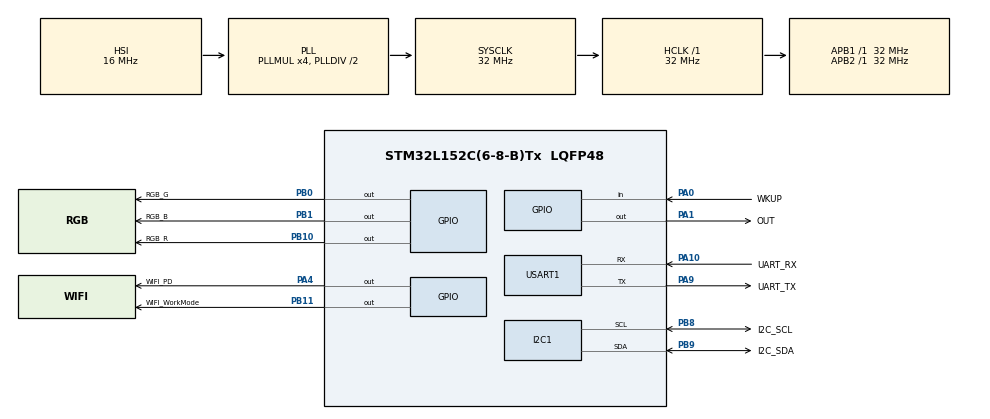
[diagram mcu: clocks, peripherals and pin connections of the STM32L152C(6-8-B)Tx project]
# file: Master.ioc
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Dma.I2C1_RX.2.Direction=DMA_PERIPH_TO_MEMORY
Dma.I2C1_RX.2.Instance=DMA1_Channel7
Dma.I2C1_RX.2.MemDataAlignment=DMA_MDATAALIGN_BYTE
Dma.I2C1_RX.2.MemInc=DMA_MINC_ENABLE
Dma.I2C1_RX.2.Mode=DMA_NORMAL
Dma.I2C1_RX.2.PeriphDataAlignment=DMA_PDATAALIGN_BYTE
Dma.I2C1_RX.2.PeriphInc=DMA_PINC_DISABLE
Dma.I2C1_RX.2.Priority=DMA_PRIORITY_MEDIUM
Dma.I2C1_TX.3.Direction=DMA_MEMORY_TO_PERIPH
Dma.I2C1_TX.3.Instance=DMA1_Channel6
Dma.I2C1_TX.3.MemDataAlignment=DMA_MDATAALIGN_BYTE
Dma.I2C1_TX.3.MemInc=DMA_MINC_ENABLE
Dma.I2C1_TX.3.Mode=DMA_NORMAL
Dma.I2C1_TX.3.PeriphDataAlignment=DMA_PDATAALIGN_BYTE
Dma.I2C1_TX.3.PeriphInc=DMA_PINC_DISABLE
Dma.I2C1_TX.3.Priority=DMA_PRIORITY_MEDIUM
Dma.Request0=USART1_RX
Dma.Request1=USART1_TX
Dma.Request2=I2C1_RX
Dma.Request3=I2C1_TX
Dma.USART1_RX.0.Direction=DMA_PERIPH_TO_MEMORY
Dma.USART1_RX.0.Instance=DMA1_Channel5
Dma.USART1_RX.0.MemDataAlignment=DMA_MDATAALIGN_BYTE
Dma.USART1_RX.0.MemInc=DMA_MINC_ENABLE
Dma.USART1_RX.0.Mode=DMA_NORMAL
Dma.USART1_RX.0.PeriphDataAlignment=DMA_PDATAALIGN_BYTE
Dma.USART1_RX.0.PeriphInc=DMA_PINC_DISABLE
Dma.USART1_RX.0.Priority=DMA_PRIORITY_HIGH
Dma.USART1_TX.1.Direction=DMA_MEMORY_TO_PERIPH
Dma.USART1_TX.1.Instance=DMA1_Channel4
Dma.USART1_TX.1.MemDataAlignment=DMA_MDATAALIGN_BYTE
Dma.USART1_TX.1.MemInc=DMA_MINC_ENABLE
Dma.USART1_TX.1.Mode=DMA_NORMAL
Dma.USART1_TX.1.PeriphDataAlignment=DMA_PDATAALIGN_BYTE
Dma.USART1_TX.1.PeriphInc=DMA_PINC_DISABLE
Dma.USART1_TX.1.Priority=DMA_PRIORITY_MEDIUM
FREERTOS.Tasks01=defaultTask,0,128,StartDefaultTask,Default
I2C1.DualAddressMode=I2C_DUALADDRESS_ENABLE
I2C1.GeneralCallMode=I2C_GENERALCALL_ENABLE
I2C1.I2C_Mode=I2C_Fast
I2C1.OwnAddress=4
Mcu.Family=STM32L1
Mcu.Name=STM32L152C(6-8-B)Tx
Mcu.Package=LQFP48
NVIC.DMA1_Channel4_IRQn=true\:5\:0\:false\:false\:true\:true
NVIC.DMA1_Channel5_IRQn=true\:5\:0\:false\:false\:true\:true
NVIC.DMA1_Channel6_IRQn=true\:5\:0\:false\:false\:true\:true
NVIC.DMA1_Channel7_IRQn=true\:5\:0\:false\:false\:true\:true
NVIC.FLASH_IRQn=true\:5\:0\:false\:false\:true\:true
NVIC.I2C1_ER_IRQn=true\:5\:0\:false\:false\:true\:true
NVIC.I2C1_EV_IRQn=true\:5\:0\:false\:false\:true\:true
NVIC.PriorityGroup=NVIC_PRIORITYGROUP_4
NVIC.TIM2_IRQn=true\:0\:0\:false\:false\:true\:false
NVIC.TimeBase=TIM2_IRQn
NVIC.TimeBaseIP=TIM2
NVIC.USART1_IRQn=true\:5\:0\:false\:false\:true\:true
PA0-WKUP1.GPIO_Label=WKUP
PA0-WKUP1.Signal=GPIO_Input
PA1.GPIO_Label=OUT
PA1.Signal=GPIO_Output
PA10.GPIO_Label=UART_RX
PA10.Mode=Asynchronous
PA10.Signal=USART1_RX
PA13.Mode=Serial_Wire
PA13.Signal=SYS_JTMS-SWDIO
PA14.Mode=Serial_Wire
PA14.Signal=SYS_JTCK-SWCLK
PA4.GPIO_Label=WIFI_PD
PA4.Signal=GPIO_Output
PA9.GPIO_Label=UART_TX
PA9.Mode=Asynchronous
PA9.Signal=USART1_TX
PB0.GPIO_Label=RGB_G
PB0.Signal=GPIO_Output
PB1.GPIO_Label=RGB_B
PB1.Signal=GPIO_Output
PB10.GPIO_Label=RGB_R
PB10.Signal=GPIO_Output
PB11.GPIO_Label=WIFI_WorkMode
PB11.GPIO_PuPd=GPIO_PULLDOWN
PB11.Signal=GPIO_Output
PB8.GPIO_Label=I2C_SCL
PB8.Mode=I2C
PB8.Signal=I2C1_SCL
PB9.GPIO_Label=I2C_SDA
PB9.Mode=I2C
PB9.Signal=I2C1_SDA
ProjectManager.HeapSize=0x200
ProjectManager.StackSize=0x400
ProjectManager.TargetToolchain=MDK-ARM V5
RCC.AHBFreq_Value=32000000
RCC.APB1Freq_Value=32000000
RCC.APB1TimFreq_Value=32000000
RCC.APB2Freq_Value=32000000
RCC.APB2TimFreq_Value=32000000
RCC.HCLKFreq_Value=32000000
RCC.HSE_VALUE=24000000
RCC.HSI_VALUE=16000000
RCC.LSE_VALUE=32768
RCC.MSIClockRange=RCC_MSIRANGE_6
RCC.MSI_VALUE=4194000
RCC.PLLMUL=RCC_PLL_MUL4
RCC.SYSCLKFreq_VALUE=32000000
RCC.SYSCLKSource=RCC_SYSCLKSOURCE_PLLCLK
RCC.USBOutput=32000000
RCC.VCOOutputFreq_Value=64000000
VP_FREERTOS_VS_ENABLE.Mode=Enabled
VP_SYS_VS_tim2.Mode=TIM2
board=Master

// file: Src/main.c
/**
  ******************************************************************************
  * File Name          : main.c
  * Description        : Main program body
  ******************************************************************************
  *
  * COPYRIGHT(c) 2016 STMicroelectronics
  *
  * Redistribution and use in source and binary forms, with or without modification,
  * are permitted provided that the following conditions are met:
  *   1. Redistributions of source code must retain the above copyright notice,
  *      this list of conditions and the following disclaimer.
  *   2. Redistributions in binary form must reproduce the above copyright notice,
  *      this list of conditions and the following disclaimer in the documentation
  *      and/or other materials provided with the distribution.
  *   3. Neither the name of STMicroelectronics nor the names of its contributors
  *      may be used to endorse or promote products derived from this software
  *      without specific prior written permission.
  *
  * THIS SOFTWARE IS PROVIDED BY THE COPYRIGHT HOLDERS AND CONTRIBUTORS "AS IS"
  * AND ANY EXPRESS OR IMPLIED WARRANTIES, INCLUDING, BUT NOT LIMITED TO, THE
  * IMPLIED WARRANTIES OF MERCHANTABILITY AND FITNESS FOR A PARTICULAR PURPOSE ARE
  * DISCLAIMED. IN NO EVENT SHALL THE COPYRIGHT HOLDER OR CONTRIBUTORS BE LIABLE
  * FOR ANY DIRECT, INDIRECT, INCIDENTAL, SPECIAL, EXEMPLARY, OR CONSEQUENTIAL
  * DAMAGES (INCLUDING, BUT NOT LIMITED TO, PROCUREMENT OF SUBSTITUTE GOODS OR
  * SERVICES; LOSS OF USE, DATA, OR PROFITS; OR BUSINESS INTERRUPTION) HOWEVER
  * CAUSED AND ON ANY THEORY OF LIABILITY, WHETHER IN CONTRACT, STRICT LIABILITY,
  * OR TORT (INCLUDING NEGLIGENCE OR OTHERWISE) ARISING IN ANY WAY OUT OF THE USE
  * OF THIS SOFTWARE, EVEN IF ADVISED OF THE POSSIBILITY OF SUCH DAMAGE.
  *
  ******************************************************************************
  */
#include "stm32l1xx_hal.h"
#include "cmsis_os.h"
#include "dma.h"
#include "i2c.h"
#include "usart.h"
#include "gpio.h"

/* USER CODE BEGIN Includes */
#include <string.h>
#include "main.h"
/* USER CODE END Includes */

/* USER CODE BEGIN PV */
/* Private variables ---------------------------------------------------------*/

/* USER CODE END PV */

void SystemClock_Config(void);
void Error_Handler(void);
void MX_FREERTOS_Init(void);

/* USER CODE BEGIN PFP */
/* Private function prototypes -----------------------------------------------*/

/* USER CODE END PFP */

int main(void)
{

  /* MCU Configuration----------------------------------------------------------*/

  /* Reset of all peripherals, Initializes the Flash interface and the Systick. */
  HAL_Init();

  /* Configure the system clock */
  SystemClock_Config();

  /* Initialize all configured peripherals */
  MX_GPIO_Init();
  MX_DMA_Init();
  MX_I2C1_Init();
  MX_USART1_UART_Init();

  /* Call init function for freertos objects (in freertos.c) */
  MX_FREERTOS_Init();

  /* Start scheduler */
  osKernelStart();

  /* We should never get here as control is now taken by the scheduler */

  /* Infinite loop */
  while (1)
  {

  }

}

/** System Clock Configuration
*/
void SystemClock_Config(void)
{

  RCC_OscInitTypeDef RCC_OscInitStruct;
  RCC_ClkInitTypeDef RCC_ClkInitStruct;

  __HAL_RCC_PWR_CLK_ENABLE();

  __HAL_PWR_VOLTAGESCALING_CONFIG(PWR_REGULATOR_VOLTAGE_SCALE1);

  RCC_OscInitStruct.OscillatorType = RCC_OSCILLATORTYPE_HSI;
  RCC_OscInitStruct.HSIState = RCC_HSI_ON;
  RCC_OscInitStruct.HSICalibrationValue = 16;
  RCC_OscInitStruct.PLL.PLLState = RCC_PLL_ON;
  RCC_OscInitStruct.PLL.PLLSource = RCC_PLLSOURCE_HSI;
  RCC_OscInitStruct.PLL.PLLMUL = RCC_PLL_MUL4;
  RCC_OscInitStruct.PLL.PLLDIV = RCC_PLL_DIV2;
  if (HAL_RCC_OscConfig(&RCC_OscInitStruct) != HAL_OK)
  {
    Error_Handler();
  }

  RCC_ClkInitStruct.ClockType = RCC_CLOCKTYPE_HCLK|RCC_CLOCKTYPE_SYSCLK
                              |RCC_CLOCKTYPE_PCLK1|RCC_CLOCKTYPE_PCLK2;
  RCC_ClkInitStruct.SYSCLKSource = RCC_SYSCLKSOURCE_PLLCLK;
  RCC_ClkInitStruct.AHBCLKDivider = RCC_SYSCLK_DIV1;
  RCC_ClkInitStruct.APB1CLKDivider = RCC_HCLK_DIV1;
  RCC_ClkInitStruct.APB2CLKDivider = RCC_HCLK_DIV1;
  if (HAL_RCC_ClockConfig(&RCC_ClkInitStruct, FLASH_LATENCY_1) != HAL_OK)
  {
    Error_Handler();
  }

  HAL_SYSTICK_Config(HAL_RCC_GetHCLKFreq()/1000);

  HAL_SYSTICK_CLKSourceConfig(SYSTICK_CLKSOURCE_HCLK);

  /* SysTick_IRQn interrupt configuration */
  HAL_NVIC_SetPriority(SysTick_IRQn, 15, 0);
}

void HAL_TIM_PeriodElapsedCallback(TIM_HandleTypeDef *htim)
{
  if (htim->Instance == TIM2) {
    HAL_IncTick();
  }
}

void Error_Handler(void)
{
  while(1)
  {
  }
}

/************************ (C) COPYRIGHT STMicroelectronics *****END OF FILE****/

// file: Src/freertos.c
/**
  ******************************************************************************
  * File Name          : freertos.c
  * Description        : Code for freertos applications
  ******************************************************************************
  *
  * COPYRIGHT(c) 2016 STMicroelectronics
  *
  * Redistribution and use in source and binary forms, with or without modification,
  * are permitted provided that the following conditions are met:
  *   1. Redistributions of source code must retain the above copyright notice,
  *      this list of conditions and the following disclaimer.
  *   2. Redistributions in binary form must reproduce the above copyright notice,
  *      this list of conditions and the following disclaimer in the documentation
  *      and/or other materials provided with the distribution.
  *   3. Neither the name of STMicroelectronics nor the names of its contributors
  *      may be used to endorse or promote products derived from this software
  *      without specific prior written permission.
  *
  * THIS SOFTWARE IS PROVIDED BY THE COPYRIGHT HOLDERS AND CONTRIBUTORS "AS IS"
  * AND ANY EXPRESS OR IMPLIED WARRANTIES, INCLUDING, BUT NOT LIMITED TO, THE
  * IMPLIED WARRANTIES OF MERCHANTABILITY AND FITNESS FOR A PARTICULAR PURPOSE ARE
  * DISCLAIMED. IN NO EVENT SHALL THE COPYRIGHT HOLDER OR CONTRIBUTORS BE LIABLE
  * FOR ANY DIRECT, INDIRECT, INCIDENTAL, SPECIAL, EXEMPLARY, OR CONSEQUENTIAL
  * DAMAGES (INCLUDING, BUT NOT LIMITED TO, PROCUREMENT OF SUBSTITUTE GOODS OR
  * SERVICES; LOSS OF USE, DATA, OR PROFITS; OR BUSINESS INTERRUPTION) HOWEVER
  * CAUSED AND ON ANY THEORY OF LIABILITY, WHETHER IN CONTRACT, STRICT LIABILITY,
  * OR TORT (INCLUDING NEGLIGENCE OR OTHERWISE) ARISING IN ANY WAY OUT OF THE USE
  * OF THIS SOFTWARE, EVEN IF ADVISED OF THE POSSIBILITY OF SUCH DAMAGE.
  *
  ******************************************************************************
  */

#include "FreeRTOS.h"
#include "task.h"
#include "cmsis_os.h"

/* USER CODE BEGIN Includes */
#include "cTask.h"
/* USER CODE END Includes */

osThreadId defaultTaskHandle;

void StartDefaultTask(void const * argument);

void MX_FREERTOS_Init(void); /* (MISRA C 2004 rule 8.1) */

/* Hook prototypes */

/* Init FreeRTOS */

void MX_FREERTOS_Init(void) {

  /* Create the thread(s) */
  /* definition and creation of defaultTask */
  osThreadDef(defaultTask, StartDefaultTask, osPriorityNormal, 0, 128);
  defaultTaskHandle = osThreadCreate(osThread(defaultTask), NULL);

  /* USER CODE BEGIN RTOS_THREADS */
  /* add threads, ... */
	cLEDs_Task();
	cTaskList();
  /* USER CODE END RTOS_THREADS */

}

/* StartDefaultTask function */
void StartDefaultTask(void const * argument)
{

  /* USER CODE BEGIN StartDefaultTask */
  /* Infinite loop */
  for(;;)
  {
		osDelay(1000);

  }
  /* USER CODE END StartDefaultTask */
}

/************************ (C) COPYRIGHT STMicroelectronics *****END OF FILE****/
